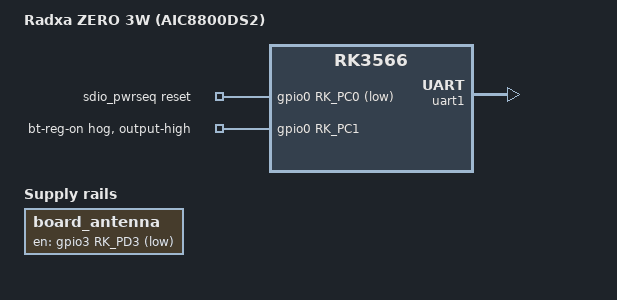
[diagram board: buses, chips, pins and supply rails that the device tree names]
// SPDX-License-Identifier: (GPL-2.0+ OR MIT)
/*
 * Radxa ZERO 3W with the AIC8800DS2 (BL-M8800DS2) SDIO module.
 *
 * The AIC8800 is detected over SDIO (0xc8a1:0x0182 bootloader, then
 * 0xc8a1:0x0082 after the firmware download).  Bluetooth is attached to the
 * bare UART1 from userspace with hciattach; there is no serdev node.
 *
 * The board wiring comes from the vendor
 * rk3566-radxa-zero-3w-aic8800ds2.dts:
 *   - WiFi reset       GPIO0_C0 (sdio-pwrseq)
 *   - Bluetooth enable GPIO0_C1, active high
 *   - BT wake / host wake GPIO0_B4 / GPIO0_B3 (unused without btlpm)
 *   - board antenna    GPIO3_D3, active low
 */

/dts-v1/;

#include "rk3566-radxa-zero-3w.dtsi"

/ {
	model = "Radxa ZERO 3W (AIC8800DS2)";
	compatible = "radxa,zero3w-aic8800ds2", "radxa,zero-3w", "rockchip,rk3566";

	sdio_pwrseq: sdio-pwrseq {
		compatible = "mmc-pwrseq-simple";
		pinctrl-names = "default";
		pinctrl-0 = <&wifi_reg_on_h>;
		reset-gpios = <&gpio0 RK_PC0 GPIO_ACTIVE_LOW>;
	};

	board_antenna: board-antenna {
		compatible = "regulator-fixed";
		enable-active-low;
		gpio = <&gpio3 RK_PD3 GPIO_ACTIVE_LOW>;
		regulator-always-on;
		regulator-boot-on;
		regulator-name = "board_antenna";
		pinctrl-names = "default";
		pinctrl-0 = <&ant_1>;
	};
};

&gpio0 {
	/*
	 * BT,reset_gpio of the vendor tree is an active-high enable line:
	 * the vendor rfkill driver leaves it high when Bluetooth is on.
	 */
	bt-reg-on-hog {
		gpio-hog;
		gpios = <RK_PC1 GPIO_ACTIVE_HIGH>;
		output-high;
		line-name = "bt-reg-on";
	};
};

&sdmmc1 {
	supports-sdio;
	disable-wp;
	rockchip,default-sample-phase = <180>;
};

&uart1 {
	/*
	 * Bare ttyS1 for hciattach.  The vendor tree drives RTS as a GPIO
	 * from its own bluetooth-platdata driver; without that driver the
	 * same pin is used in hardware flow-control mode, which is what
	 * "hciattach ... flow" needs.
	 */
	pinctrl-names = "default";
	pinctrl-0 = <&uart1m0_xfer &uart1m0_ctsn &uart1m0_rtsn>;
	uart-has-rtscts;
	status = "okay";
};
